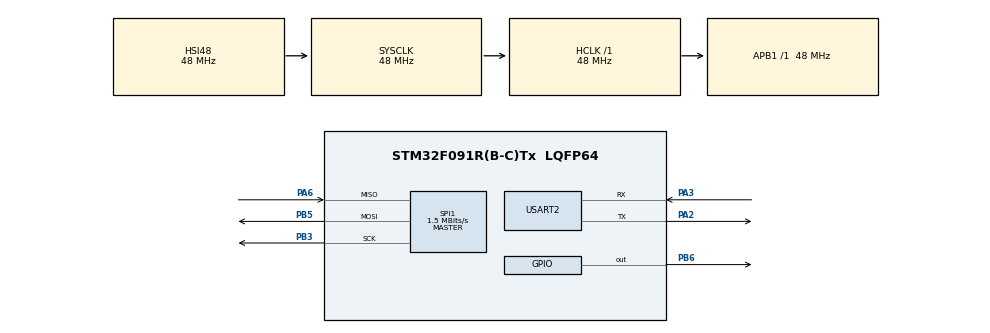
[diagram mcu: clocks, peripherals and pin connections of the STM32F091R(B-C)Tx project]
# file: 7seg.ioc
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Mcu.Family=STM32F0
Mcu.Name=STM32F091R(B-C)Tx
Mcu.Package=LQFP64
NVIC.TIM2_IRQn=true\:0\:0\:false\:false\:true\:true\:true\:true
NVIC.USART2_IRQn=true\:0\:0\:false\:false\:true\:true\:true\:true
PA2.Mode=Asynchronous
PA2.Signal=USART2_TX
PA3.Mode=Asynchronous
PA3.Signal=USART2_RX
PA6.Mode=Full_Duplex_Master
PA6.Signal=SPI1_MISO
PB3.Mode=Full_Duplex_Master
PB3.Signal=SPI1_SCK
PB5.Mode=Full_Duplex_Master
PB5.Signal=SPI1_MOSI
PB6.Signal=GPIO_Output
PF0-OSC_IN.Mode=HSE-External-Oscillator
PF0-OSC_IN.Signal=RCC_OSC_IN
PF1-OSC_OUT.Mode=HSE-External-Oscillator
PF1-OSC_OUT.Signal=RCC_OSC_OUT
ProjectManager.HeapSize=0x200
ProjectManager.StackSize=0x400
ProjectManager.TargetToolchain=STM32CubeIDE
RCC.AHBFreq_Value=48000000
RCC.APB1Freq_Value=48000000
RCC.APB1TimFreq_Value=48000000
RCC.HCLKFreq_Value=48000000
RCC.SYSCLKFreq_VALUE=48000000
RCC.SYSCLKSource=RCC_SYSCLKSOURCE_HSI48
SPI1.BaudRatePrescaler=SPI_BAUDRATEPRESCALER_32
SPI1.CalculateBaudRate=1.5 MBits/s
SPI1.DataSize=SPI_DATASIZE_8BIT
SPI1.Direction=SPI_DIRECTION_2LINES
SPI1.Mode=SPI_MODE_MASTER
SPI1.NSSPMode=SPI_NSS_PULSE_DISABLE
SPI1.VirtualType=VM_MASTER
TIM2.AutoReloadPreload=TIM_AUTORELOAD_PRELOAD_ENABLE
TIM2.Period=4800
TIM2.Prescaler=1000
USART2.VirtualMode-Asynchronous=VM_ASYNC
VP_TIM2_VS_ClockSourceINT.Mode=Internal
board=custom

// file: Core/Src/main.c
/* USER CODE BEGIN Header */
/**
  ******************************************************************************
  * @file           : main.c
  * @brief          : Main program body
  ******************************************************************************
  * @attention
  *
  * Copyright (c) 2023 STMicroelectronics.
  * All rights reserved.
  *
  * This software is licensed under terms that can be found in the LICENSE file
  * in the root directory of this software component.
  * If no LICENSE file comes with this software, it is provided AS-IS.
  *
  ******************************************************************************
  */
/* USER CODE END Header */
#include "main.h"

SPI_HandleTypeDef hspi1;
TIM_HandleTypeDef htim2;
UART_HandleTypeDef huart2;

/* USER CODE BEGIN PV */
// 25AA040A instructions
const uint8_t EEPROM_READ = 0b00000011;
const uint8_t EEPROM_WRITE = 0b00000010;
const uint8_t EEPROM_WREN = 0b00000110;	//write enable
uint8_t segmentSelect;
uint8_t displaySelect;
const int latchPin = ((uint16_t)0x1000U);   // pb12 nss
const int clockPin = ((uint16_t)0x2000U);   // pb13 sck
const int dataPin = ((uint16_t)0x8000U);    // pb15 mosi
uint8_t txdata[30] = "Testing 7seg interrupt";
char spi_buf[20];
char uart_buf[50];
int uart_buf_len;
uint8_t addr;
uint8_t wip;
/* USER CODE END PV */

void SystemClock_Config(void);
static void MX_GPIO_Init(void);
static void MX_USART2_UART_Init(void);
static void MX_TIM2_Init(void);
static void MX_SPI1_Init(void);

int main(void)
{
  HAL_Init();
  SystemClock_Config();

  /* Initialize all configured peripherals */
  MX_GPIO_Init();
  MX_USART2_UART_Init();
  MX_TIM2_Init();
  MX_SPI1_Init();

  HAL_TIM_Base_Start_IT(&htim2);	//start timer 2
  HAL_GPIO_WritePin(GPIOB, latchPin, GPIO_PIN_SET);	//set initial state of latch pin as high
  segmentSelect = 0x00;
  displaySelect = 0x01;
  while (1)
  {

  }
}

void SystemClock_Config(void)
{
  RCC_OscInitTypeDef RCC_OscInitStruct = {0};
  RCC_ClkInitTypeDef RCC_ClkInitStruct = {0};
  RCC_PeriphCLKInitTypeDef PeriphClkInit = {0};

  /** Initializes the RCC Oscillators according to the specified parameters
  * in the RCC_OscInitTypeDef structure.
  */
  RCC_OscInitStruct.OscillatorType = RCC_OSCILLATORTYPE_HSI48;
  RCC_OscInitStruct.HSI48State = RCC_HSI48_ON;
  RCC_OscInitStruct.PLL.PLLState = RCC_PLL_NONE;
  if (HAL_RCC_OscConfig(&RCC_OscInitStruct) != HAL_OK)
  {
    Error_Handler();
  }

  /** Initializes the CPU, AHB and APB buses clocks
  */
  RCC_ClkInitStruct.ClockType = RCC_CLOCKTYPE_HCLK|RCC_CLOCKTYPE_SYSCLK
                              |RCC_CLOCKTYPE_PCLK1;
  RCC_ClkInitStruct.SYSCLKSource = RCC_SYSCLKSOURCE_HSI48;
  RCC_ClkInitStruct.AHBCLKDivider = RCC_SYSCLK_DIV1;
  RCC_ClkInitStruct.APB1CLKDivider = RCC_HCLK_DIV1;

  if (HAL_RCC_ClockConfig(&RCC_ClkInitStruct, FLASH_LATENCY_1) != HAL_OK)
  {
    Error_Handler();
  }
  PeriphClkInit.PeriphClockSelection = RCC_PERIPHCLK_USART2;
  PeriphClkInit.Usart2ClockSelection = RCC_USART2CLKSOURCE_PCLK1;
  if (HAL_RCCEx_PeriphCLKConfig(&PeriphClkInit) != HAL_OK)
  {
    Error_Handler();
  }
}

static void MX_SPI1_Init(void)
{

  /* SPI1 parameter configuration*/
  hspi1.Instance = SPI1;
  hspi1.Init.Mode = SPI_MODE_MASTER;
  hspi1.Init.Direction = SPI_DIRECTION_2LINES;
  hspi1.Init.DataSize = SPI_DATASIZE_8BIT;
  hspi1.Init.CLKPolarity = SPI_POLARITY_LOW;
  hspi1.Init.CLKPhase = SPI_PHASE_1EDGE;
  hspi1.Init.NSS = SPI_NSS_SOFT;
  hspi1.Init.BaudRatePrescaler = SPI_BAUDRATEPRESCALER_32;
  hspi1.Init.FirstBit = SPI_FIRSTBIT_MSB;
  hspi1.Init.TIMode = SPI_TIMODE_DISABLE;
  hspi1.Init.CRCCalculation = SPI_CRCCALCULATION_DISABLE;
  hspi1.Init.CRCPolynomial = 7;
  hspi1.Init.CRCLength = SPI_CRC_LENGTH_DATASIZE;
  hspi1.Init.NSSPMode = SPI_NSS_PULSE_DISABLE;
  if (HAL_SPI_Init(&hspi1) != HAL_OK)
  {
    Error_Handler();
  }

}

static void MX_TIM2_Init(void)
{

  TIM_ClockConfigTypeDef sClockSourceConfig = {0};
  TIM_MasterConfigTypeDef sMasterConfig = {0};

  htim2.Instance = TIM2;
  htim2.Init.Prescaler = 1000;
  htim2.Init.CounterMode = TIM_COUNTERMODE_UP;
  htim2.Init.Period = 4800;
  htim2.Init.ClockDivision = TIM_CLOCKDIVISION_DIV1;
  htim2.Init.AutoReloadPreload = TIM_AUTORELOAD_PRELOAD_ENABLE;
  if (HAL_TIM_Base_Init(&htim2) != HAL_OK)
  {
    Error_Handler();
  }
  sClockSourceConfig.ClockSource = TIM_CLOCKSOURCE_INTERNAL;
  if (HAL_TIM_ConfigClockSource(&htim2, &sClockSourceConfig) != HAL_OK)
  {
    Error_Handler();
  }
  sMasterConfig.MasterOutputTrigger = TIM_TRGO_RESET;
  sMasterConfig.MasterSlaveMode = TIM_MASTERSLAVEMODE_DISABLE;
  if (HAL_TIMEx_MasterConfigSynchronization(&htim2, &sMasterConfig) != HAL_OK)
  {
    Error_Handler();
  }

}

static void MX_USART2_UART_Init(void)
{
  /* USER CODE END USART2_Init 1 */
  huart2.Instance = USART2;
  huart2.Init.BaudRate = 115200;
  huart2.Init.WordLength = UART_WORDLENGTH_8B;
  huart2.Init.StopBits = UART_STOPBITS_1;
  huart2.Init.Parity = UART_PARITY_NONE;
  huart2.Init.Mode = UART_MODE_TX_RX;
  huart2.Init.HwFlowCtl = UART_HWCONTROL_NONE;
  huart2.Init.OverSampling = UART_OVERSAMPLING_16;
  huart2.Init.OneBitSampling = UART_ONE_BIT_SAMPLE_DISABLE;
  huart2.AdvancedInit.AdvFeatureInit = UART_ADVFEATURE_NO_INIT;
  if (HAL_UART_Init(&huart2) != HAL_OK)
  {
    Error_Handler();
  }
}

static void MX_GPIO_Init(void)
{
  GPIO_InitTypeDef GPIO_InitStruct = {0};

  /* GPIO Ports Clock Enable */
  __HAL_RCC_GPIOF_CLK_ENABLE();
  __HAL_RCC_GPIOA_CLK_ENABLE();
  __HAL_RCC_GPIOB_CLK_ENABLE();

  /*Configure GPIO pin Output Level */
  HAL_GPIO_WritePin(GPIOB, GPIO_PIN_6, GPIO_PIN_RESET);

  /*Configure GPIO pin : PB6 */
  GPIO_InitStruct.Pin = GPIO_PIN_6;
  GPIO_InitStruct.Mode = GPIO_MODE_OUTPUT_PP;
  GPIO_InitStruct.Pull = GPIO_NOPULL;
  GPIO_InitStruct.Speed = GPIO_SPEED_FREQ_LOW;
  HAL_GPIO_Init(GPIOB, &GPIO_InitStruct);

}

void HAL_TIM_PeriodElapsedCallback(TIM_HandleTypeDef* htim)
{
	  // Say something
	  uart_buf_len = sprintf(uart_buf, "SPI Test\r\n");
	  HAL_UART_Transmit(&huart2, (uint8_t *)uart_buf, uart_buf_len, 100);

	  // write segment select
	  HAL_GPIO_WritePin(GPIOB, GPIO_PIN_6, GPIO_PIN_RESET);
	  HAL_SPI_Transmit(&hspi1, (uint8_t *)&segmentSelect, 1, 100);
	  HAL_SPI_Receive(&hspi1, (uint8_t *)spi_buf, 1, 100);
	  HAL_GPIO_WritePin(GPIOB, GPIO_PIN_6, GPIO_PIN_SET);
	  // write display select
	  HAL_GPIO_WritePin(GPIOB, GPIO_PIN_6, GPIO_PIN_RESET);
	  HAL_SPI_Transmit(&hspi1, (uint8_t *)&displaySelect, 1, 100);
	  HAL_SPI_Receive(&hspi1, (uint8_t *)spi_buf, 1, 100);
	  HAL_GPIO_WritePin(GPIOB, GPIO_PIN_6, GPIO_PIN_SET);

	  displaySelect = displaySelect << 1;
	  if(displaySelect == 0x00)
	  {
		  displaySelect = 0x01;
	  }
}

void Error_Handler(void)
{
  __disable_irq();
  while (1)
  {
  }
}
